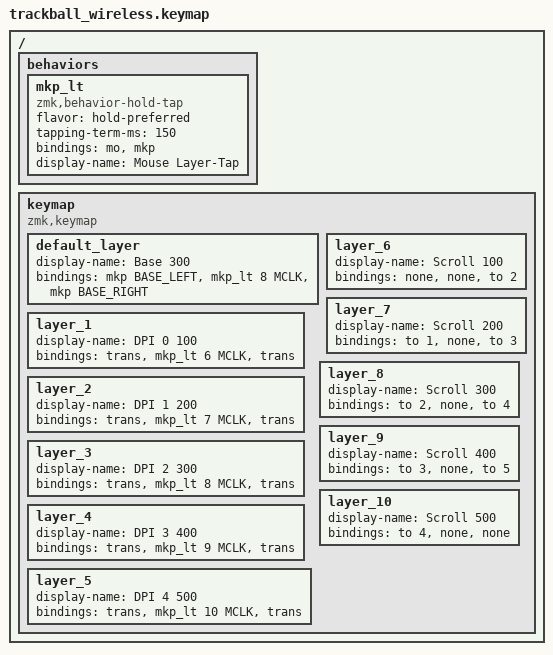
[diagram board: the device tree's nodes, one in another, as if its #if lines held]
// Trackball Wireless keymap
//
// 3 buttons, positions from zmk,kscan-gpio-direct:
//   0 left    D7
//   1 middle  D8
//   2 right   D9
//
// Behaviour
//   left tap              left click
//   middle tap            middle click
//   middle hold           vertical scroll mode, held
//   right tap             right click
//   middle hold + left    DPI down one step
//   middle hold + right   DPI up one step
//   left button held while plugging USB in    bootloader, see trackball_boot_button.c
//
// Layer map
//   0  base, DPI step 2, 300, the default
//   1  DPI step 0, 100
//   2  DPI step 1, 200
//   3  DPI step 2, 300      addressable so the default step can be restored
//   4  DPI step 3, 400
//   5  DPI step 4, 500
//   6  scroll + step 0
//   7  scroll + step 1
//   8  scroll + step 2
//   9  scroll + step 3
//  10  scroll + step 4
//
// No combos, so every button press goes out at once. Left handed is a separate
// build: trackball_wireless_left.keymap defines LEFT_HANDED and includes this
// file, which swaps left and right on the base layer. Nothing else differs.
#ifdef LEFT_HANDED
#define BASE_LEFT RCLK
#define BASE_RIGHT LCLK
#else
#define BASE_LEFT LCLK
#define BASE_RIGHT RCLK
#endif

#include <behaviors.dtsi>
#include <dt-bindings/zmk/keys.h>
#include <dt-bindings/zmk/pointing.h>
#include <dt-bindings/zmk/bt.h>
#include <dt-bindings/zmk/outputs.h>

/ {
    behaviors {
        // Same as &lt, but the tap side is a mouse key. &lt hardcodes its tap
        // binding to &kp, so &lt 7 MCLK sends a keyboard usage, and MCLK is
        // BIT(2), which is HID usage 4, which is the letter a.
        mkp_lt: mkp_lt {
            compatible = "zmk,behavior-hold-tap";
            #binding-cells = <2>;
            // Any other button pressed while this is down makes it a hold at once,
            // so middle plus left or right is always a DPI step, never a stray click.
            flavor = "hold-preferred";
            tapping-term-ms = <150>;
            bindings = <&mo>, <&mkp>;
            display-name = "Mouse Layer-Tap";
        };
    };

    keymap {
        compatible = "zmk,keymap";

        default_layer {
            display-name = "Base 300";
            bindings = <
                &mkp BASE_LEFT  &mkp_lt 8 MCLK  &mkp BASE_RIGHT
            >;
        };

        layer_1 {
            display-name = "DPI 0 100";
            bindings = <
                &trans      &mkp_lt 6 MCLK  &trans
            >;
        };

        layer_2 {
            display-name = "DPI 1 200";
            bindings = <
                &trans      &mkp_lt 7 MCLK  &trans
            >;
        };

        layer_3 {
            display-name = "DPI 2 300";
            bindings = <
                &trans      &mkp_lt 8 MCLK  &trans
            >;
        };

        layer_4 {
            display-name = "DPI 3 400";
            bindings = <
                &trans      &mkp_lt 9 MCLK  &trans
            >;
        };

        layer_5 {
            display-name = "DPI 4 500";
            bindings = <
                &trans      &mkp_lt 10 MCLK  &trans
            >;
        };

        // Scroll layers. Left and right step the DPI instead of clicking, and
        // &to also leaves scroll mode so the new DPI applies straight away.
        layer_6 {
            display-name = "Scroll 100";
            bindings = <
                &none  &none  &to 2
            >;
        };

        layer_7 {
            display-name = "Scroll 200";
            bindings = <
                &to 1  &none  &to 3
            >;
        };

        layer_8 {
            display-name = "Scroll 300";
            bindings = <
                &to 2  &none  &to 4
            >;
        };

        layer_9 {
            display-name = "Scroll 400";
            bindings = <
                &to 3  &none  &to 5
            >;
        };

        layer_10 {
            display-name = "Scroll 500";
            bindings = <
                &to 4  &none  &none
            >;
        };
    };
};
